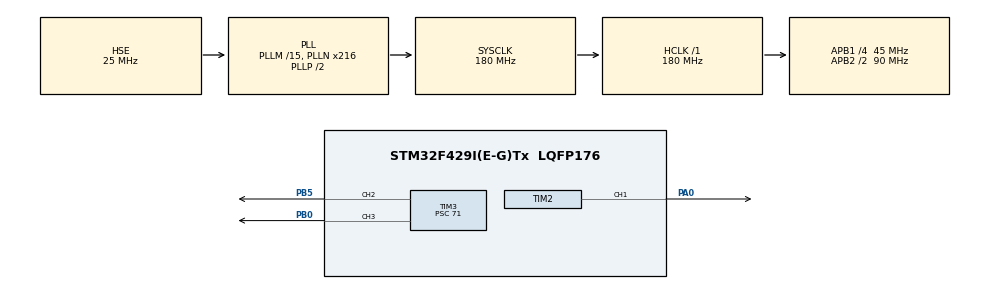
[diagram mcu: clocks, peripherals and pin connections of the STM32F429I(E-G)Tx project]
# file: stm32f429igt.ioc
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Mcu.Family=STM32F4
Mcu.Name=STM32F429I(E-G)Tx
Mcu.Package=LQFP176
NVIC.PriorityGroup=NVIC_PRIORITYGROUP_4
PA0/WKUP.Signal=S_TIM2_CH1_ETR
PA13.Mode=Serial_Wire
PA13.Signal=SYS_JTMS-SWDIO
PA14.Mode=Serial_Wire
PA14.Signal=SYS_JTCK-SWCLK
PB0.Signal=S_TIM3_CH3
PB5.Signal=S_TIM3_CH2
PH0/OSC_IN.Mode=HSE-External-Oscillator
PH0/OSC_IN.Signal=RCC_OSC_IN
PH1/OSC_OUT.Mode=HSE-External-Oscillator
PH1/OSC_OUT.Signal=RCC_OSC_OUT
ProjectManager.HeapSize=0x200
ProjectManager.StackSize=0x400
ProjectManager.TargetToolchain=MDK-ARM V5.32
RCC.48MHZClocksFreq_Value=90000000
RCC.AHBFreq_Value=180000000
RCC.APB1CLKDivider=RCC_HCLK_DIV4
RCC.APB1Freq_Value=45000000
RCC.APB1TimFreq_Value=90000000
RCC.APB2CLKDivider=RCC_HCLK_DIV2
RCC.APB2Freq_Value=90000000
RCC.APB2TimFreq_Value=180000000
RCC.CortexFreq_Value=180000000
RCC.HCLKFreq_Value=180000000
RCC.HSE_VALUE=25000000
RCC.HSI_VALUE=16000000
RCC.LSE_VALUE=32768
RCC.PLLM=15
RCC.PLLN=216
RCC.PLLSourceVirtual=RCC_PLLSOURCE_HSE
RCC.SYSCLKFreq_VALUE=180000000
RCC.SYSCLKSource=RCC_SYSCLKSOURCE_PLLCLK
RCC.VCOOutputFreq_Value=360000000
SH.S_TIM2_CH1_ETR.0=TIM2_CH1,PWM Generation1 CH1
SH.S_TIM3_CH2.0=TIM3_CH2,PWM Generation2 CH2
SH.S_TIM3_CH3.0=TIM3_CH3,PWM Generation3 CH3
TIM2.Channel-PWM\ Generation1\ CH1=TIM_CHANNEL_1
TIM2.OCMode_PWM-PWM\ Generation1\ CH1=TIM_OCMODE_PWM1
TIM2.OCPolarity_1=TIM_OCPOLARITY_LOW
TIM2.Period=999
TIM2.Prescaler=71
TIM2.Pulse-PWM\ Generation1\ CH1=500
TIM3.Channel-PWM\ Generation2\ CH2=TIM_CHANNEL_2
TIM3.Channel-PWM\ Generation3\ CH3=TIM_CHANNEL_3
TIM3.OCPolarity_3=TIM_OCPOLARITY_LOW
TIM3.Period=999
TIM3.Prescaler=71
VP_TIM2_VS_ClockSourceINT.Mode=Internal
VP_TIM3_VS_ClockSourceINT.Mode=Internal
board=custom

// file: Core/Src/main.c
/* USER CODE BEGIN Header */
/**
  ******************************************************************************
  * @file           : main.c
  * @brief          : Main program body
  ******************************************************************************
  * @attention
  *
  * Copyright (c) 2025 STMicroelectronics.
  * All rights reserved.
  *
  * This software is licensed under terms that can be found in the LICENSE file
  * in the root directory of this software component.
  * If no LICENSE file comes with this software, it is provided AS-IS.
  *
  ******************************************************************************
  */
/* USER CODE END Header */
#include "main.h"
#include "tim.h"
#include "gpio.h"

void SystemClock_Config(void);

int main(void)
{

  /* MCU Configuration--------------------------------------------------------*/

  /* Reset of all peripherals, Initializes the Flash interface and the Systick. */
  HAL_Init();

  /* Configure the system clock */
  SystemClock_Config();

  /* Initialize all configured peripherals */
  MX_GPIO_Init();
  MX_TIM2_Init();
  MX_TIM3_Init();
  /* USER CODE BEGIN 2 */
	HAL_GPIO_TogglePin(GPIOB,GPIO_PIN_0);
  HAL_TIM_PWM_Start(&htim3, TIM_CHANNEL_3);
	HAL_TIM_PWM_Start(&htim3, TIM_CHANNEL_2);
  //__HAL_TIM_SET_COMPARE(&htim3, TIM_CHANNEL_3, 100);
  /* USER CODE END 2 */

  /* Infinite loop */
  /* USER CODE BEGIN WHILE */
  while (1)
  {
		//HAL_GPIO_TogglePin(GPIOB,GPIO_PIN_0);
		//HAL_GPIO_TogglePin(GPIOB,GPIO_PIN_1);//��ת��ƽ
		for(int i=0;i<1000;i+=10){
      __HAL_TIM_SET_COMPARE(&htim3, TIM_CHANNEL_2, i);
			__HAL_TIM_SET_COMPARE(&htim3, TIM_CHANNEL_3, i);
		  HAL_Delay(5);
    }
		//HAL_Delay(200);
    for(int i=1000;i>0;i-=10){
      __HAL_TIM_SET_COMPARE(&htim3, TIM_CHANNEL_2, i);
			__HAL_TIM_SET_COMPARE(&htim3, TIM_CHANNEL_3, i);
		  HAL_Delay(5);
    }
		//HAL_Delay(200);

    /* USER CODE END WHILE */

  }
}

void SystemClock_Config(void)
{
  RCC_OscInitTypeDef RCC_OscInitStruct = {0};
  RCC_ClkInitTypeDef RCC_ClkInitStruct = {0};

  /** Configure the main internal regulator output voltage
  */
  __HAL_RCC_PWR_CLK_ENABLE();
  __HAL_PWR_VOLTAGESCALING_CONFIG(PWR_REGULATOR_VOLTAGE_SCALE1);

  /** Initializes the RCC Oscillators according to the specified parameters
  * in the RCC_OscInitTypeDef structure.
  */
  RCC_OscInitStruct.OscillatorType = RCC_OSCILLATORTYPE_HSE;
  RCC_OscInitStruct.HSEState = RCC_HSE_ON;
  RCC_OscInitStruct.PLL.PLLState = RCC_PLL_ON;
  RCC_OscInitStruct.PLL.PLLSource = RCC_PLLSOURCE_HSE;
  RCC_OscInitStruct.PLL.PLLM = 15;
  RCC_OscInitStruct.PLL.PLLN = 216;
  RCC_OscInitStruct.PLL.PLLP = RCC_PLLP_DIV2;
  RCC_OscInitStruct.PLL.PLLQ = 4;
  if (HAL_RCC_OscConfig(&RCC_OscInitStruct) != HAL_OK)
  {
    Error_Handler();
  }

  /** Activate the Over-Drive mode
  */
  if (HAL_PWREx_EnableOverDrive() != HAL_OK)
  {
    Error_Handler();
  }

  /** Initializes the CPU, AHB and APB buses clocks
  */
  RCC_ClkInitStruct.ClockType = RCC_CLOCKTYPE_HCLK|RCC_CLOCKTYPE_SYSCLK
                              |RCC_CLOCKTYPE_PCLK1|RCC_CLOCKTYPE_PCLK2;
  RCC_ClkInitStruct.SYSCLKSource = RCC_SYSCLKSOURCE_PLLCLK;
  RCC_ClkInitStruct.AHBCLKDivider = RCC_SYSCLK_DIV1;
  RCC_ClkInitStruct.APB1CLKDivider = RCC_HCLK_DIV4;
  RCC_ClkInitStruct.APB2CLKDivider = RCC_HCLK_DIV2;

  if (HAL_RCC_ClockConfig(&RCC_ClkInitStruct, FLASH_LATENCY_5) != HAL_OK)
  {
    Error_Handler();
  }
}

void Error_Handler(void)
{
  __disable_irq();
  while (1)
  {
  }
}
